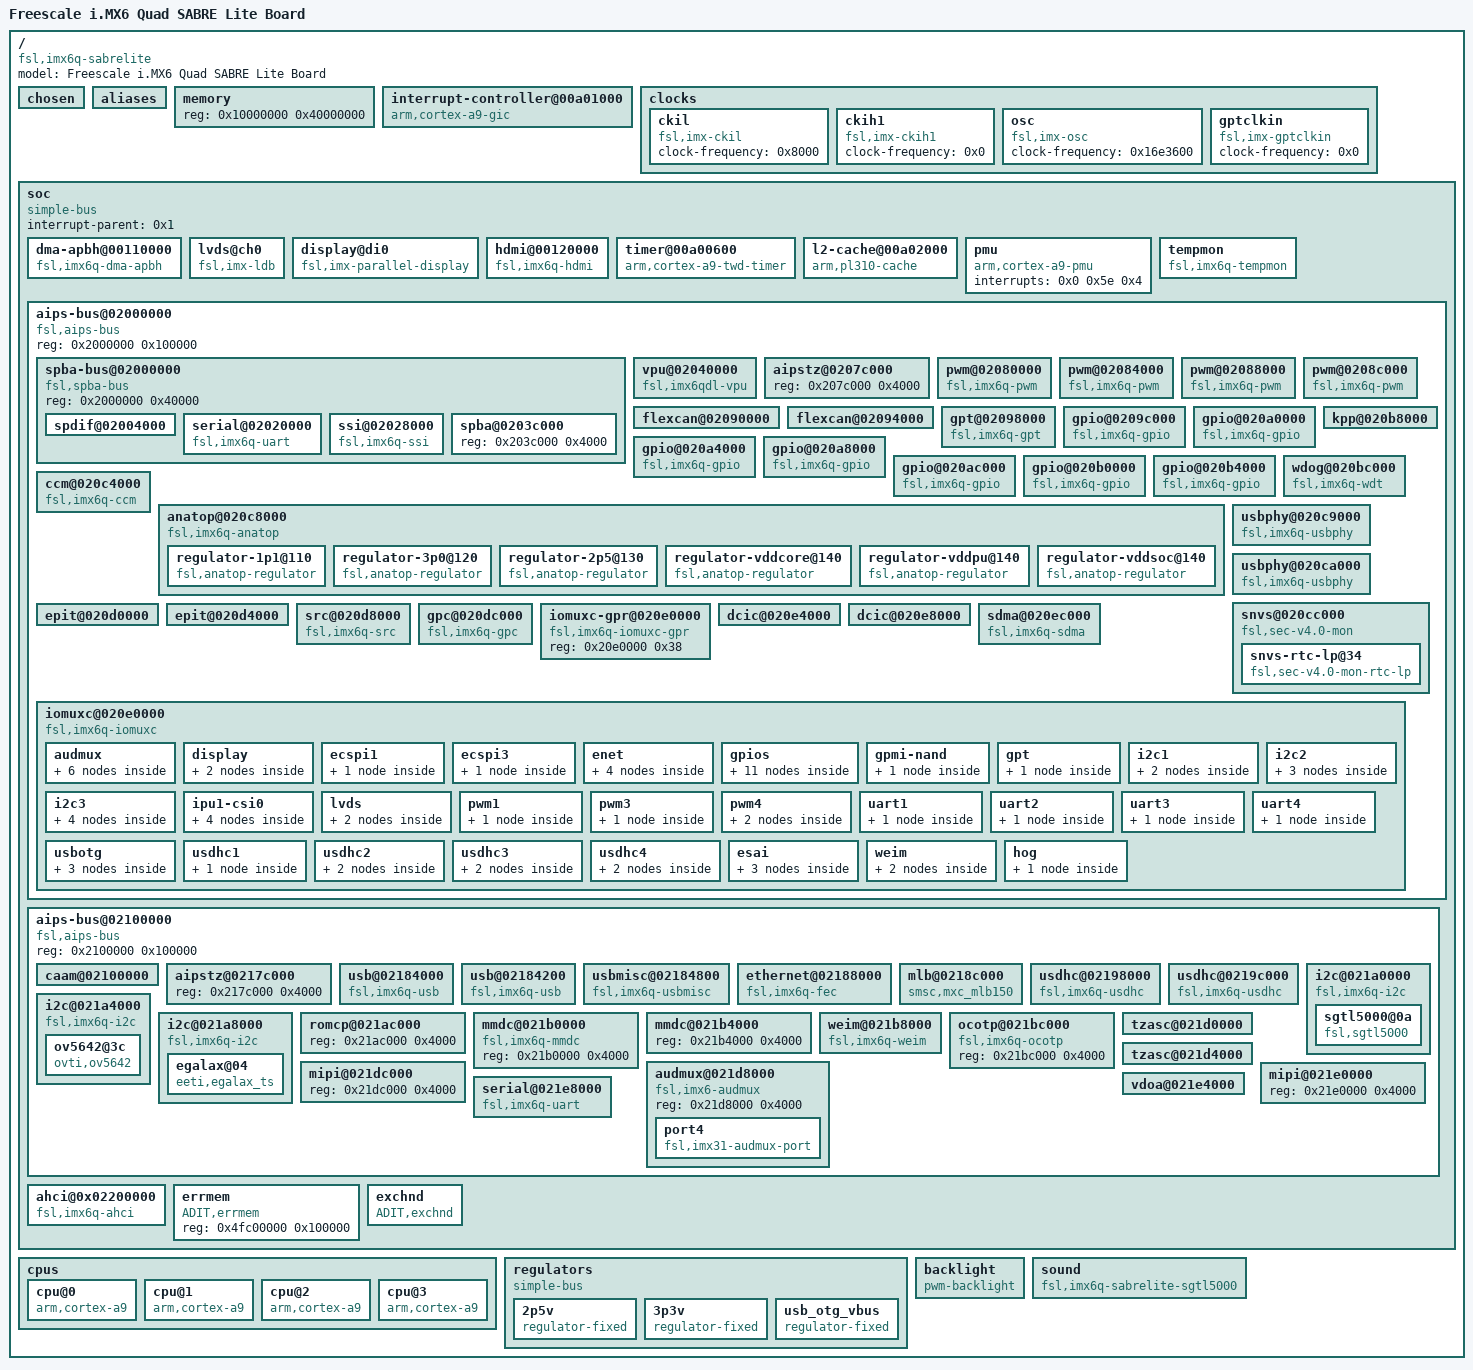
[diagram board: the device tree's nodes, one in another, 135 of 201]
/dts-v1/;

/ {
	#address-cells = <0x1>;
	#size-cells = <0x1>;
	model = "Freescale i.MX6 Quad SABRE Lite Board";
	compatible = "fsl,imx6q-sabrelite", "fsl,imx6q";

	chosen {
	   bootargs = "console=ttymxc1 root=/dev/mmcblk0p1 rw rootwait earlyprintk init_debug=1 video=mxcfb0 vmalloc=400M mem=862M fbmem=10M no_console_suspend";
//	   bootargs = "console=ttymxc1,115200 root=/dev/mmcblk0 rw rootwait earlyprintk init_debug mem=862M no_console_suspend";
	};

	aliases {
		serial0 = "/soc/aips-bus@02000000/spba-bus@02000000/serial@02020000";
		serial1 = "/soc/aips-bus@02100000/serial@021e8000";
		serial2 = "/soc/aips-bus@02100000/serial@021ec000";
		serial3 = "/soc/aips-bus@02100000/serial@021f0000";
		serial4 = "/soc/aips-bus@02100000/serial@021f4000";
		gpio0 = "/soc/aips-bus@02000000/gpio@0209c000";
		gpio1 = "/soc/aips-bus@02000000/gpio@020a0000";
		gpio2 = "/soc/aips-bus@02000000/gpio@020a4000";
		gpio3 = "/soc/aips-bus@02000000/gpio@020a8000";
		gpio4 = "/soc/aips-bus@02000000/gpio@020ac000";
		gpio5 = "/soc/aips-bus@02000000/gpio@020b0000";
		gpio6 = "/soc/aips-bus@02000000/gpio@020b4000";
	};

	memory {
		device_type = "memory";
		reg = <0x10000000 0x40000000>;
	};

	interrupt-controller@00a01000 {
		compatible = "arm,cortex-a9-gic";
		#interrupt-cells = <0x3>;
		#address-cells = <0x1>;
		#size-cells = <0x1>;
		interrupt-controller;
		reg = <0xa01000 0x1000 0xa00100 0x100>;
		linux,phandle = <0x1>;
		phandle = <0x1>;
	};

	clocks {
		#address-cells = <0x1>;
		#size-cells = <0x0>;

		ckil {
			compatible = "fsl,imx-ckil", "fixed-clock";
			clock-frequency = <0x8000>;
		};

		ckih1 {
			compatible = "fsl,imx-ckih1", "fixed-clock";
			clock-frequency = <0x0>;
		};

		osc {
			compatible = "fsl,imx-osc", "fixed-clock";
			clock-frequency = <0x16e3600>;
		};

		gptclkin {
			compatible = "fsl,imx-gptclkin", "fixed-clock";
			clock-frequency = <0x0>;
		};
	};

	soc {
		#address-cells = <0x1>;
		#size-cells = <0x1>;
		compatible = "simple-bus";
		interrupt-parent = <0x1>;
		ranges;

		dma-apbh@00110000 {
			compatible = "fsl,imx6q-dma-apbh", "fsl,imx28-dma-apbh";
			reg = <0x110000 0x2000>;
			clocks = <0x2 0x6a>;
		};

		lvds@ch0 {
			compatible = "fsl,imx-ldb";
			clocks = <0x2 0x87 0x2 0x88 0x2 0x21 0x2 0x22 0x2 0x27 0x2 0x28 0x2 0x29 0x2 0x2a>;
			clock-names = "ldb_di0", "ldb_di1", "ldb_di0_sel", "ldb_di1_sel", "ipu1_di0_sel", "ipu1_di1_sel", "ipu2_di0_sel", "ipu2_di1_sel";
			fsl,ldb-channel = <0x0>;
			status = "okay";
			crtcs = <0x3 0x4>;
			pinctrl-names = "default";
			pinctrl-0 = <0x5>;
			bgref-rmode = "internal";
		};

		display@di0 {
			compatible = "fsl,imx-parallel-display";
			status = "okay";
			xres = <0x320>;
			yres = <0x1e0>;
			clock = <0x1c9c380>;
			left_margin = <0x28>;
			right_margin = <0x28>;
			upper_margin = <0x1d>;
			lower_margin = <0xd>;
			hsync_len = <0x30>;
			vsync_len = <0x3>;
			crtcs = <0x3>;
			pinctrl-names = "default";
			pinctrl-0 = <0x8>;
			interface_pix_fmt = "rgb18";
		};

		hdmi@00120000 {
			compatible = "fsl,imx6q-hdmi", "fsl,hdmi";
			reg = <0x120000 0x9000>;
			interrupts = <0x0 0x73 0x4>;
			clocks = <0x2 0x7c 0x2 0x7b 0x2 0x4f 0x2 0x50 0x2 0x51 0x2 0x52 0x2 0x27 0x2 0x28 0x2 0x29 0x2 0x2a>;
			clock-names = "isfr", "iahb", "ipu1_di0_pre", "ipu1_di1_pre", "ipu2_di0_pre", "ipu2_di1_pre", "ipu1_di0_sel", "ipu1_di1_sel", "ipu2_di0_sel", "ipu2_di1_sel";
			status = "okay";
			crtcs = <0x3 0x6 0x4 0x7>;
			ddc = <0x9>;
		};

		timer@00a00600 {
			compatible = "arm,cortex-a9-twd-timer";
			reg = <0xa00600 0x20>;
			interrupts = <0x1 0xd 0xf01>;
		};

		l2-cache@00a02000 {
			compatible = "arm,pl310-cache";
			reg = <0xa02000 0x1000>;
			interrupts = <0x0 0x5c 0x4>;
			cache-unified;
			cache-level = <0x2>;
			arm,tag-latency = <0x4 0x2 0x3>;
			arm,data-latency = <0x4 0x2 0x3>;
			linux,phandle = <0x28>;
			phandle = <0x28>;
		};

		pmu {
			compatible = "arm,cortex-a9-pmu";
			interrupts = <0x0 0x5e 0x4>;
		};

		tempmon {
			compatible = "fsl,imx6q-tempmon";
			fsl,tempmon = <0xa>;
			fsl,tempmon-data = <0xb>;
		};

		aips-bus@02000000 {
			compatible = "fsl,aips-bus", "simple-bus";
			#address-cells = <0x1>;
			#size-cells = <0x1>;
			reg = <0x2000000 0x100000>;
			ranges;

			spba-bus@02000000 {
				compatible = "fsl,spba-bus", "simple-bus";
				#address-cells = <0x1>;
				#size-cells = <0x1>;
				reg = <0x2000000 0x40000>;
				ranges;

				spdif@02004000 {
					reg = <0x2004000 0x4000>;
					interrupts = <0x0 0x34 0x4>;
				};
/*
				ecspi@02008000 {
					#address-cells = <0x1>;
					#size-cells = <0x0>;
					compatible = "fsl,imx6q-ecspi", "fsl,imx51-ecspi";
					reg = <0x2008000 0x4000>;
					interrupts = <0x0 0x1f 0x4>;
					clocks = <0x2 0x70 0x2 0x70>;
					clock-names = "ipg", "per";
					status = "okay";
					fsl,spi-num-chipselects = <0x1>;
					cs-gpios = <0xc 0x13 0x0>;
					pinctrl-names = "default";
					pinctrl-0 = <0xd>;
					fsl,spi-dma-enable = <0x1>;
					fsl,spi-dma-events = <0x3 0x4>;
					fsl,spi-automode = <0x1>;
					fsl,spi-max-pio-trans = <0x400>;

					m25p80@0 {
						#address-cells = <0x1>;
						#size-cells = <0x1>;
						compatible = "sst,sst25vf016b";
						spi-max-frequency = <0x1312d00>;
						reg = <0x0>;
					};
				};
*/
				serial@02020000 {
					compatible = "fsl,imx6q-uart", "fsl,imx21-uart";
					reg = <0x2020000 0x4000>;
					interrupts = <0x0 0x1a 0x4>;
					clocks = <0x2 0xa0 0x2 0xa1>;
					clock-names = "ipg", "per";
					status = "okay";
				};

				ssi@02028000 {
					compatible = "fsl,imx6q-ssi", "fsl,imx21-ssi";
					reg = <0x2028000 0x4000>;
					interrupts = <0x0 0x2e 0x4>;
					clocks = <0x2 0x55 0x2 0xb2>;
					clock-names = "mclk", "ipg";
					fsl,fifo-depth = <0xf>;
					fsl,ssi-dma-events = <0x26 0x25>;
					status = "okay";
					fsl,mode = "i2s-slave";
					linux,phandle = <0x20>;
					phandle = <0x20>;
				};

				spba@0203c000 {
					reg = <0x203c000 0x4000>;
				};
			};

			vpu@02040000 {
				compatible = "fsl,imx6qdl-vpu";
				reg = <0x2040000 0x3c000>;
				interrupts = <0x0 0xc 0x4 0x0 0x3 0x4>;
			};

			aipstz@0207c000 {
				reg = <0x207c000 0x4000>;
			};

			pwm@02080000 {
				#pwm-cells = <0x3>;
				compatible = "fsl,imx6q-pwm", "fsl,imx27-pwm";
				reg = <0x2080000 0x4000>;
				interrupts = <0x0 0x53 0x4>;
				clocks = <0x2 0x3e 0x2 0x91>;
				clock-names = "ipg", "per";
			};

			pwm@02084000 {
				#pwm-cells = <0x3>;
				compatible = "fsl,imx6q-pwm", "fsl,imx27-pwm";
				reg = <0x2084000 0x4000>;
				interrupts = <0x0 0x54 0x4>;
				clocks = <0x2 0x3e 0x2 0x92>;
				clock-names = "ipg", "per";
			};

			pwm@02088000 {
				#pwm-cells = <0x3>;
				compatible = "fsl,imx6q-pwm", "fsl,imx27-pwm";
				reg = <0x2088000 0x4000>;
				interrupts = <0x0 0x55 0x4>;
				clocks = <0x2 0x3e 0x2 0x93>;
				clock-names = "ipg", "per";
			};

			pwm@0208c000 {
				#pwm-cells = <0x3>;
				compatible = "fsl,imx6q-pwm", "fsl,imx27-pwm";
				reg = <0x208c000 0x4000>;
				interrupts = <0x0 0x56 0x4>;
				clocks = <0x2 0x3e 0x2 0x94>;
				clock-names = "ipg", "per";
				pinctrl-names = "default";
				pinctrl-0 = <0xe>;
				status = "okay";
				linux,phandle = <0x2c>;
				phandle = <0x2c>;
			};

			flexcan@02090000 {
				reg = <0x2090000 0x4000>;
				interrupts = <0x0 0x6e 0x4>;
			};

			flexcan@02094000 {
				reg = <0x2094000 0x4000>;
				interrupts = <0x0 0x6f 0x4>;
			};

			gpt@02098000 {
				compatible = "fsl,imx6q-gpt";
				reg = <0x2098000 0x4000>;
				interrupts = <0x0 0x37 0x4>;
				clocks = <0x2 0x78>;
				clock-names = "ckih";
			};

			gpio@0209c000 {
				compatible = "fsl,imx6q-gpio", "fsl,imx35-gpio";
				reg = <0x209c000 0x4000>;
				interrupts = <0x0 0x42 0x4 0x0 0x43 0x4>;
				gpio-controller;
				#gpio-cells = <0x2>;
				interrupt-controller;
				#interrupt-cells = <0x2>;
				linux,phandle = <0x1e>;
				phandle = <0x1e>;
			};

			gpio@020a0000 {
				compatible = "fsl,imx6q-gpio", "fsl,imx35-gpio";
				reg = <0x20a0000 0x4000>;
				interrupts = <0x0 0x44 0x4 0x0 0x45 0x4>;
				gpio-controller;
				#gpio-cells = <0x2>;
				interrupt-controller;
				#interrupt-cells = <0x2>;
				linux,phandle = <0x1a>;
				phandle = <0x1a>;
			};

			gpio@020a4000 {
				compatible = "fsl,imx6q-gpio", "fsl,imx35-gpio";
				reg = <0x20a4000 0x4000>;
				interrupts = <0x0 0x46 0x4 0x0 0x47 0x4>;
				gpio-controller;
				#gpio-cells = <0x2>;
				interrupt-controller;
				#interrupt-cells = <0x2>;
				linux,phandle = <0xc>;
				phandle = <0xc>;
			};

			gpio@020a8000 {
				compatible = "fsl,imx6q-gpio", "fsl,imx35-gpio";
				reg = <0x20a8000 0x4000>;
				interrupts = <0x0 0x48 0x4 0x0 0x49 0x4>;
				gpio-controller;
				#gpio-cells = <0x2>;
				interrupt-controller;
				#interrupt-cells = <0x2>;
			};

			gpio@020ac000 {
				compatible = "fsl,imx6q-gpio", "fsl,imx35-gpio";
				reg = <0x20ac000 0x4000>;
				interrupts = <0x0 0x4a 0x4 0x0 0x4b 0x4>;
				gpio-controller;
				#gpio-cells = <0x2>;
				interrupt-controller;
				#interrupt-cells = <0x2>;
			};

			gpio@020b0000 {
				compatible = "fsl,imx6q-gpio", "fsl,imx35-gpio";
				reg = <0x20b0000 0x4000>;
				interrupts = <0x0 0x4c 0x4 0x0 0x4d 0x4>;
				gpio-controller;
				#gpio-cells = <0x2>;
				interrupt-controller;
				#interrupt-cells = <0x2>;
			};

			gpio@020b4000 {
				compatible = "fsl,imx6q-gpio", "fsl,imx35-gpio";
				reg = <0x20b4000 0x4000>;
				interrupts = <0x0 0x4e 0x4 0x0 0x4f 0x4>;
				gpio-controller;
				#gpio-cells = <0x2>;
				interrupt-controller;
				#interrupt-cells = <0x2>;
				linux,phandle = <0x17>;
				phandle = <0x17>;
			};

			kpp@020b8000 {
				reg = <0x20b8000 0x4000>;
				interrupts = <0x0 0x52 0x4>;
			};

			wdog@020bc000 {
				compatible = "fsl,imx6q-wdt", "fsl,imx21-wdt";
				reg = <0x20bc000 0x4000>;
				interrupts = <0x0 0x50 0x4>;
				clocks = <0x2 0x0>;
			};

			ccm@020c4000 {
				compatible = "fsl,imx6q-ccm";
				reg = <0x20c4000 0x4000>;
				interrupts = <0x0 0x57 0x4 0x0 0x58 0x4>;
				#clock-cells = <0x1>;
				linux,phandle = <0x2>;
				phandle = <0x2>;
			};

			anatop@020c8000 {
				compatible = "fsl,imx6q-anatop", "syscon", "simple-bus";
				reg = <0x20c8000 0x1000>;
				interrupts = <0x0 0x31 0x4 0x0 0x36 0x4 0x0 0x7f 0x4>;
				linux,phandle = <0xa>;
				phandle = <0xa>;

				regulator-1p1@110 {
					compatible = "fsl,anatop-regulator";
					regulator-name = "vdd1p1";
					regulator-min-microvolt = <0xc3500>;
					regulator-max-microvolt = <0x14fb18>;
					regulator-always-on;
					anatop-reg-offset = <0x110>;
					anatop-vol-bit-shift = <0x8>;
					anatop-vol-bit-width = <0x5>;
					anatop-min-bit-val = <0x4>;
					anatop-min-voltage = <0xc3500>;
					anatop-max-voltage = <0x14fb18>;
				};

				regulator-3p0@120 {
					compatible = "fsl,anatop-regulator";
					regulator-name = "vdd3p0";
					regulator-min-microvolt = <0x2ab980>;
					regulator-max-microvolt = <0x3010b0>;
					regulator-always-on;
					anatop-reg-offset = <0x120>;
					anatop-vol-bit-shift = <0x8>;
					anatop-vol-bit-width = <0x5>;
					anatop-min-bit-val = <0x0>;
					anatop-min-voltage = <0x280de8>;
					anatop-max-voltage = <0x33e140>;
				};

				regulator-2p5@130 {
					compatible = "fsl,anatop-regulator";
					regulator-name = "vdd2p5";
					regulator-min-microvolt = <0x1e8480>;
					regulator-max-microvolt = <0x29f630>;
					regulator-always-on;
					anatop-reg-offset = <0x130>;
					anatop-vol-bit-shift = <0x8>;
					anatop-vol-bit-width = <0x5>;
					anatop-min-bit-val = <0x0>;
					anatop-min-voltage = <0x1e8480>;
					anatop-max-voltage = <0x29f630>;
				};

				regulator-vddcore@140 {
					compatible = "fsl,anatop-regulator";
					regulator-name = "cpu";
					regulator-min-microvolt = <0xb1008>;
					regulator-max-microvolt = <0x162010>;
					regulator-always-on;
					anatop-reg-offset = <0x140>;
					anatop-vol-bit-shift = <0x0>;
					anatop-vol-bit-width = <0x5>;
					anatop-delay-reg-offset = <0x170>;
					anatop-delay-bit-shift = <0x18>;
					anatop-delay-bit-width = <0x2>;
					anatop-min-bit-val = <0x1>;
					anatop-min-voltage = <0xb1008>;
					anatop-max-voltage = <0x162010>;
					linux,phandle = <0x29>;
					phandle = <0x29>;
				};

				regulator-vddpu@140 {
					compatible = "fsl,anatop-regulator";
					regulator-name = "vddpu";
					regulator-min-microvolt = <0xb1008>;
					regulator-max-microvolt = <0x162010>;
					regulator-always-on;
					anatop-reg-offset = <0x140>;
					anatop-vol-bit-shift = <0x9>;
					anatop-vol-bit-width = <0x5>;
					anatop-delay-reg-offset = <0x170>;
					anatop-delay-bit-shift = <0x1a>;
					anatop-delay-bit-width = <0x2>;
					anatop-min-bit-val = <0x1>;
					anatop-min-voltage = <0xb1008>;
					anatop-max-voltage = <0x162010>;
					linux,phandle = <0x2a>;
					phandle = <0x2a>;
				};

				regulator-vddsoc@140 {
					compatible = "fsl,anatop-regulator";
					regulator-name = "vddsoc";
					regulator-min-microvolt = <0xb1008>;
					regulator-max-microvolt = <0x162010>;
					regulator-always-on;
					anatop-reg-offset = <0x140>;
					anatop-vol-bit-shift = <0x12>;
					anatop-vol-bit-width = <0x5>;
					anatop-delay-reg-offset = <0x170>;
					anatop-delay-bit-shift = <0x1c>;
					anatop-delay-bit-width = <0x2>;
					anatop-min-bit-val = <0x1>;
					anatop-min-voltage = <0xb1008>;
					anatop-max-voltage = <0x162010>;
					linux,phandle = <0x2b>;
					phandle = <0x2b>;
				};
			};

			usbphy@020c9000 {
				compatible = "fsl,imx6q-usbphy", "fsl,imx23-usbphy";
				reg = <0x20c9000 0x1000 0x20c8000 0x200>;
				interrupts = <0x0 0x2c 0x4>;
				clocks = <0x2 0xb6>;
				usbphy_reg_at_anatop;
				usbphy_need_disconnect_line_feature;
				usbphy_need_open_regulator_at_lpm;
				linux,phandle = <0x10>;
				phandle = <0x10>;
			};

			usbphy@020ca000 {
				compatible = "fsl,imx6q-usbphy", "fsl,imx23-usbphy";
				reg = <0x20ca000 0x1000 0x20c8000 0x200>;
				interrupts = <0x0 0x2d 0x4>;
				clocks = <0x2 0xb7>;
				usbphy_reg_at_anatop;
				usbphy_need_open_regulator_at_lpm;
				linux,phandle = <0x14>;
				phandle = <0x14>;
			};

			snvs@020cc000 {
				compatible = "fsl,sec-v4.0-mon", "simple-bus";
				#address-cells = <0x1>;
				#size-cells = <0x1>;
				ranges = <0x0 0x20cc000 0x4000>;

				snvs-rtc-lp@34 {
					compatible = "fsl,sec-v4.0-mon-rtc-lp";
					reg = <0x34 0x58>;
					interrupts = <0x0 0x13 0x4 0x0 0x14 0x4>;
				};
			};

			epit@020d0000 {
				reg = <0x20d0000 0x4000>;
				interrupts = <0x0 0x38 0x4>;
			};

			epit@020d4000 {
				reg = <0x20d4000 0x4000>;
				interrupts = <0x0 0x39 0x4>;
			};

			src@020d8000 {
				compatible = "fsl,imx6q-src";
				reg = <0x20d8000 0x4000>;
				interrupts = <0x0 0x5b 0x4 0x0 0x60 0x4>;
			};

			gpc@020dc000 {
				compatible = "fsl,imx6q-gpc";
				reg = <0x20dc000 0x4000>;
				interrupts = <0x0 0x59 0x4 0x0 0x5a 0x4>;
			};

			iomuxc-gpr@020e0000 {
				compatible = "fsl,imx6q-iomuxc-gpr", "syscon";
				reg = <0x20e0000 0x38>;
			};

			dcic@020e4000 {
				reg = <0x20e4000 0x4000>;
				interrupts = <0x0 0x7c 0x4>;
			};

			dcic@020e8000 {
				reg = <0x20e8000 0x4000>;
				interrupts = <0x0 0x7d 0x4>;
			};


			sdma@020ec000 {
				compatible = "fsl,imx6q-sdma", "fsl,imx35-sdma";
				reg = <0x20ec000 0x4000>;
				interrupts = <0x0 0x2 0x4>;
				clocks = <0x2 0x9b 0x2 0x9b>;
				clock-names = "ipg", "ahb";
				fsl,sdma-ram-script-name = "imx/sdma/sdma-imx6q-to1.bin";
			};


			iomuxc@020e0000 {
				compatible = "fsl,imx6q-iomuxc";
				reg = <0x20e0000 0x4000>;
				pinctrl-names = "default";
				pinctrl-0 = <0xf>;

				audmux {

					audmux-1 {
						fsl,pins = <0x54 0x368 0x7b4 0x3 0x0 0x80000000 0x35c 0x744 0x7c4 0x3 0x1 0x80000000 0x50 0x364 0x7b8 0x3 0x0 0x80000000 0x4c 0x360 0x7c8 0x3 0x0 0x80000000>;
					};

					audmux-2 {
						fsl,pins = <0x274 0x644 0x0 0x4 0x0 0x80000000 0x268 0x638 0x0 0x4 0x0 0x80000000 0x26c 0x63c 0x0 0x4 0x0 0x80000000 0x270 0x640 0x0 0x4 0x0 0x80000000>;
					};

					audmux-port-3 {
						fsl,pins = <0x268 0x638 0x0 0x4 0x0 0x80000000 0x26c 0x63c 0x0 0x4 0x0 0x80000000 0x270 0x640 0x0 0x4 0x0 0x80000000 0x274 0x644 0x0 0x4 0x0 0x80000000 0x280 0x650 0x0 0x1 0x0 0x80000000 0x284 0x654 0x0 0x1 0x0 0x80000000>;
					};

					audmux-port-4 {
						fsl,pins = <0x54 0x368 0x7b4 0x3 0x0 0x80000000 0x358 0x740 0x7bc 0x3 0x1 0x80000000 0x354 0x73c 0x7c0 0x3 0x1 0x80000000 0x35c 0x744 0x7c4 0x3 0x1 0x80000000 0x50 0x364 0x7b8 0x3 0x0 0x80000000 0x1c4 0x4d8 0x7b8 0x3 0x1 0x80000000 0x4c 0x360 0x7c8 0x3 0x0 0x80000000>;
						linux,phandle = <0x22>;
						phandle = <0x22>;
					};

					audmux-port-5 {
						fsl,pins = <0x1b0 0x4c4 0x7dc 0x3 0x0 0x80000000 0x1b4 0x4c8 0x7d0 0x3 0x0 0x80000000 0x1b8 0x4cc 0x7e0 0x3 0x0 0x80000000 0x204 0x5d4 0x7cc 0x2 0x1 0x80000000 0x1a8 0x4bc 0x7d4 0x3 0x1 0x80000000 0xb4 0x3c8 0x7d8 0x6 0x0 0x80000000>;
					};

					audmux-port-6 {
						fsl,pins = <0x160 0x474 0x0 0x2 0x0 0x80000000 0x164 0x478 0x0 0x2 0x0 0x80000000 0x168 0x47c 0x0 0x2 0x0 0x80000000 0x16c 0x480 0x0 0x2 0x0 0x80000000 0x184 0x498 0x0 0x3 0x0 0x80000000 0x188 0x49c 0x0 0x3 0x0 0x80000000>;
					};
				};

				display {

					display_1 {
						fsl,pins = <0x15c 0x470 0x0 0x0 0x0 0x80000000 0x160 0x474 0x0 0x0 0x0 0x80000000 0x164 0x478 0x0 0x0 0x0 0x80000000 0x168 0x47c 0x0 0x0 0x0 0x80000000 0x16c 0x480 0x0 0x0 0x0 0x80000000 0x170 0x484 0x0 0x0 0x0 0x80000000 0x174 0x488 0x0 0x0 0x0 0x80000000 0x178 0x48c 0x0 0x0 0x0 0x80000000 0x17c 0x490 0x0 0x0 0x0 0x80000000 0x180 0x494 0x0 0x0 0x0 0x80000000 0x184 0x498 0x0 0x0 0x0 0x80000000 0x188 0x49c 0x0 0x0 0x0 0x80000000 0x18c 0x4a0 0x0 0x0 0x0 0x80000000 0x190 0x4a4 0x0 0x0 0x0 0x80000000 0x194 0x4a8 0x0 0x0 0x0 0x80000000 0x198 0x4ac 0x0 0x0 0x0 0x80000000 0x19c 0x4b0 0x0 0x0 0x0 0x80000000 0x1a0 0x4b4 0x0 0x0 0x0 0x80000000 0x1a4 0x4b8 0x0 0x0 0x0 0x80000000 0x1a8 0x4bc 0x0 0x0 0x0 0x80000000 0x1ac 0x4c0 0x0 0x0 0x0 0x80000000 0x1b0 0x4c4 0x0 0x0 0x0 0x80000000 0x1b4 0x4c8 0x0 0x0 0x0 0x80000000>;
						linux,phandle = <0x8>;
						phandle = <0x8>;
					};

					display_2 {
						fsl,pins = <0x15c 0x470 0x0 0x1 0x0 0x80000000 0x160 0x474 0x0 0x1 0x0 0x80000000 0x164 0x478 0x0 0x1 0x0 0x80000000 0x168 0x47c 0x0 0x1 0x0 0x80000000 0x16c 0x480 0x0 0x1 0x0 0x80000000 0x170 0x484 0x0 0x1 0x0 0x80000000 0x174 0x488 0x0 0x1 0x0 0x80000000 0x178 0x48c 0x0 0x1 0x0 0x80000000 0x17c 0x490 0x0 0x1 0x0 0x80000000 0x180 0x494 0x0 0x1 0x0 0x80000000 0x184 0x498 0x0 0x1 0x0 0x80000000 0x188 0x49c 0x0 0x1 0x0 0x80000000 0x18c 0x4a0 0x0 0x1 0x0 0x80000000 0x190 0x4a4 0x0 0x1 0x0 0x80000000 0x194 0x4a8 0x0 0x1 0x0 0x80000000 0x198 0x4ac 0x0 0x1 0x0 0x80000000 0x19c 0x4b0 0x0 0x1 0x0 0x80000000 0x1a0 0x4b4 0x0 0x1 0x0 0x80000000 0x1a4 0x4b8 0x0 0x1 0x0 0x80000000 0x1a8 0x4bc 0x0 0x1 0x0 0x80000000 0x1ac 0x4c0 0x0 0x1 0x0 0x80000000 0x1b0 0x4c4 0x0 0x1 0x0 0x80000000 0x1b4 0x4c8 0x0 0x1 0x0 0x80000000>;
					};
				};

				ecspi1 {

					ecspi1grp-1 {
						fsl,pins = <0x94 0x3a8 0x7f8 0x1 0x0 0x1b0b0 0x98 0x3ac 0x7fc 0x1 0x0 0x1b0b0 0x90 0x3a4 0x7f4 0x1 0x0 0x1b0b0>;
						linux,phandle = <0xd>;
						phandle = <0xd>;
					};
				};

				ecspi3 {

					ecspi3grp-1 {
						fsl,pins = <0x178 0x48c 0x0 0x2 0x0 0x1b0b0 0x174 0x488 0x0 0x2 0x0 0x1b0b0 0x170 0x484 0x0 0x2 0x0 0x1b0b0>;
					};
				};

				enet {

					enetgrp-1 {
						fsl,pins = <0x1d0 0x4e4 0x840 0x1 0x0 0x1b0b0 0x1f4 0x508 0x0 0x1 0x0 0x1b0b0 0x58 0x36c 0x0 0x1 0x0 0x13030 0x5c 0x370 0x0 0x1 0x0 0x1b030 0x60 0x374 0x0 0x1 0x0 0x1b030 0x64 0x378 0x0 0x1 0x0 0x1b030 0x68 0x37c 0x0 0x1 0x0 0x1b030 0x74 0x388 0x0 0x1 0x0 0x13030 0x1d4 0x4e8 0x0 0x1 0x0 0x1b0b0 0x84 0x398 0x844 0x1 0x0 0x13030 0x70 0x384 0x848 0x1 0x0 0x1b030 0x78 0x38c 0x84c 0x1 0x0 0x1b030 0x7c 0x390 0x850 0x1 0x0 0x1b030 0x80 0x394 0x854 0x1 0x0 0x1b030 0x6c 0x380 0x858 0x1 0x0 0x13030 0x248 0x618 0x83c 0x2 0x1 0x4001b0a8>;
					};

					enetgrp-2 {
						fsl,pins = <0x200 0x5d0 0x840 0x1 0x1 0x1b0b0 0x208 0x5d8 0x0 0x4 0x0 0x1b0b0 0x58 0x36c 0x0 0x1 0x0 0x13030 0x5c 0x370 0x0 0x1 0x0 0x1b030 0x60 0x374 0x0 0x1 0x0 0x1b030 0x64 0x378 0x0 0x1 0x0 0x1b030 0x68 0x37c 0x0 0x1 0x0 0x1b030 0x74 0x388 0x0 0x1 0x0 0x13030 0x1d4 0x4e8 0x0 0x1 0x0 0x1b0b0 0x84 0x398 0x844 0x1 0x0 0x13030 0x70 0x384 0x848 0x1 0x0 0x1b030 0x78 0x38c 0x84c 0x1 0x0 0x1b030 0x7c 0x390 0x850 0x1 0x0 0x1b030 0x80 0x394 0x854 0x1 0x0 0x1b030 0x6c 0x380 0x858 0x1 0x0 0x13030>;
					};

					enetgrp-3 {
						fsl,pins = <0x1d0 0x4e4 0x840 0x1 0x0 0x1b0b0 0x1f4 0x508 0x0 0x1 0x0 0x1b0b0 0x58 0x36c 0x0 0x1 0x0 0x13030 0x5c 0x370 0x0 0x1 0x0 0x1b030 0x60 0x374 0x0 0x1 0x0 0x1b030 0x64 0x378 0x0 0x1 0x0 0x1b030 0x68 0x37c 0x0 0x1 0x0 0x1b030 0x74 0x388 0x0 0x1 0x0 0x13030 0x1d4 0x4e8 0x0 0x1 0x0 0x1b0b0 0x84 0x398 0x844 0x1 0x0 0x13030 0x70 0x384 0x848 0x1 0x0 0x1b030 0x78 0x38c 0x84c 0x1 0x0 0x1b030 0x7c 0x390 0x850 0x1 0x0 0x1b030 0x80 0x394 0x854 0x1 0x0 0x1b030 0x6c 0x380 0x858 0x1 0x0 0x13030 0x1e8 0x4fc 0x0 0x1 0x0 0x1b0b0>;
					};

					enetgrp-4 {
						fsl,pins = <0x1d0 0x4e4 0x840 0x1 0x0 0x1b0b0 0x1f4 0x508 0x0 0x1 0x0 0x1b0b0 0x58 0x36c 0x0 0x1 0x0 0x1b0b0 0x5c 0x370 0x0 0x1 0x0 0x1b0b0 0x60 0x374 0x0 0x1 0x0 0x1b0b0 0x64 0x378 0x0 0x1 0x0 0x1b0b0 0x68 0x37c 0x0 0x1 0x0 0x1b0b0 0x74 0x388 0x0 0x1 0x0 0x1b0b0 0x1d4 0x4e8 0x0 0x1 0x0 0x1b0b0 0x84 0x398 0x844 0x1 0x0 0x1b0b0 0x70 0x384 0x848 0x1 0x0 0x1b0b0 0x78 0x38c 0x84c 0x1 0x0 0x1b0b0 0x7c 0x390 0x850 0x1 0x0 0x1b0b0 0x80 0x394 0x854 0x1 0x0 0x1b0b0 0x6c 0x380 0x858 0x1 0x0 0x1b0b0>;
						linux,phandle = <0x15>;
						phandle = <0x15>;
					};
				};

				gpios {

					gpio_1_1 {
						fsl,pins = <0x224 0x5f4 0x0 0x5 0x0 0x80000000>;
					};

					gpio_1_13 {
						fsl,pins = <0x50 0x364 0x0 0x5 0x0 0x80000000>;
					};

					gpio_1_15 {
						fsl,pins = <0x54 0x368 0x0 0x5 0x0 0x80000000>;
					};

					gpio_2_0 {
						fsl,pins = <0x2fc 0x6e4 0x0 0x5 0x0 0x80000000>;
					};

					gpio_2_1 {
						fsl,pins = <0x300 0x6e8 0x0 0x5 0x0 0x80000000>;
					};

					gpio_2_2 {
						fsl,pins = <0x304 0x6ec 0x0 0x5 0x0 0x80000000>;
					};

					gpio_2_3 {
						fsl,pins = <0x308 0x6f0 0x0 0x5 0x0 0x80000000>;
					};

					gpio_2_28 {
						fsl,pins = <0x10c 0x420 0x0 0x5 0x0 0x80000000>;
					};

					gpio_5_4 {
						fsl,pins = <0xd4 0x3e8 0x0 0x5 0x0 0x80000000>;
					};

					gpio_5_20 {
						fsl,pins = <0x260 0x630 0x0 0x5 0x0 0x80000000>;
					};

					gpio_6_15 {
						fsl,pins = <0x2ec 0x6d4 0x0 0x5 0x0 0x80000000>;
					};
				};

				gpmi-nand {

					gpmi-nand-1 {
						fsl,pins = <0x2d4 0x6bc 0x0 0x0 0x0 0xb0b1 0x2d8 0x6c0 0x0 0x0 0x0 0xb0b1 0x2dc 0x6c4 0x0 0x0 0x0 0xb0b1 0x2e0 0x6c8 0x0 0x0 0x0 0xb000 0x2e4 0x6cc 0x0 0x0 0x0 0xb0b1 0x2e8 0x6d0 0x0 0x0 0x0 0xb0b1 0x2f4 0x6dc 0x0 0x1 0x0 0xb0b1 0x2f8 0x6e0 0x0 0x1 0x0 0xb0b1 0x2fc 0x6e4 0x0 0x0 0x0 0xb0b1 0x300 0x6e8 0x0 0x0 0x0 0xb0b1 0x304 0x6ec 0x0 0x0 0x0 0xb0b1 0x308 0x6f0 0x0 0x0 0x0 0xb0b1 0x30c 0x6f4 0x0 0x0 0x0 0xb0b1 0x310 0x6f8 0x0 0x0 0x0 0xb0b1 0x314 0x6fc 0x0 0x0 0x0 0xb0b1 0x318 0x700 0x0 0x0 0x0 0xb0b1 0x31c 0x704 0x0 0x2 0x0 0xb1>;
					};
				};

				gpt {

					gptgrp-1 {
						fsl,pins = <0x350 0x738 0x0 0x3 0x0 0x1b0b0>;
					};
				};

				i2c1 {

					i2c1grp-1 {
						fsl,pins = <0xa4 0x3b8 0x898 0x6 0x0 0x4001b0b0 0xc4 0x3d8 0x89c 0x1 0x0 0x4001b0b0>;
						linux,phandle = <0x1b>;
						phandle = <0x1b>;
					};

					i2c1grp-2 {
						fsl,pins = <0x278 0x648 0x89c 0x4 0x1 0x4001b0b0 0x27c 0x64c 0x898 0x4 0x1 0x4001b0b0>;
					};
				};

				i2c2 {

					i2c2grp-1 {
						fsl,pins = <0x8c 0x3a0 0x8a0 0x6 0x0 0x4001b0b0 0x90 0x3a4 0x8a4 0x6 0x0 0x4001b0b0>;
					};

					i2c2grp-2 {
						fsl,pins = <0x8c 0x3a0 0x8a0 0x6 0x0 0x4001b0b0 0x214 0x5e4 0x8a4 0x4 0x1 0x4001b0b0>;
					};

					i2c2grp-3 {
						fsl,pins = <0x210 0x5e0 0x8a0 0x4 0x1 0x4001b0b0 0x214 0x5e4 0x8a4 0x4 0x1 0x4001b0b0>;
						linux,phandle = <0x1d>;
						phandle = <0x1d>;
					};
				};

				i2c3 {

					i2c3grp-1 {
						fsl,pins = <0x94 0x3a8 0x8a8 0x6 0x0 0x4001b0b0 0x98 0x3ac 0x8ac 0x6 0x0 0x4001b0b0>;
					};

					i2c3grp-2 {
						fsl,pins = <0x22c 0x5fc 0x8a8 0x2 0x1 0x4001b0b0 0x230 0x600 0x8ac 0x2 0x1 0x4001b0b0>;
					};

					i2c3grp-3 {
						fsl,pins = <0x22c 0x5fc 0x8a8 0x2 0x1 0x4001b0b0 0x98 0x3ac 0x8ac 0x6 0x0 0x4001b0b0>;
					};

					i2c3grp-4 {
						fsl,pins = <0x23c 0x60c 0x8a8 0x6 0x2 0x4001b0b0 0x248 0x618 0x8ac 0x6 0x2 0x4001b0b0>;
						linux,phandle = <0x1f>;
						phandle = <0x1f>;
					};
				};

				ipu1-csi0 {

					ipu1-csi0-d4-d7 {
						fsl,pins = <0x268 0x638 0x0 0x0 0x0 0x80000000 0x26c 0x63c 0x0 0x0 0x0 0x80000000 0x270 0x640 0x0 0x0 0x0 0x80000000 0x274 0x644 0x0 0x0 0x0 0x80000000>;
					};

					ipu1-csi0-1 {
						fsl,pins = <0x278 0x648 0x0 0x0 0x0 0x80000000 0x27c 0x64c 0x0 0x0 0x0 0x80000000 0x280 0x650 0x0 0x0 0x0 0x80000000 0x284 0x654 0x0 0x0 0x0 0x80000000 0x288 0x658 0x0 0x0 0x0 0x80000000 0x28c 0x65c 0x0 0x0 0x0 0x80000000 0x290 0x660 0x0 0x0 0x0 0x80000000 0x294 0x664 0x0 0x0 0x0 0x80000000 0x298 0x668 0x0 0x0 0x0 0x80000000 0x29c 0x66c 0x0 0x0 0x0 0x80000000 0x2a0 0x670 0x0 0x0 0x0 0x80000000 0x2a4 0x674 0x0 0x0 0x0 0x80000000 0x25c 0x62c 0x0 0x0 0x0 0x80000000 0x258 0x628 0x0 0x0 0x0 0x80000000 0x264 0x634 0x0 0x0 0x0 0x80000000>;
						linux,phandle = <0x25>;
						phandle = <0x25>;
					};

					ipu1-csi0-2 {
						fsl,pins = <0x288 0x658 0x0 0x0 0x0 0x80000000 0x28c 0x65c 0x0 0x0 0x0 0x80000000 0x290 0x660 0x0 0x0 0x0 0x80000000 0x294 0x664 0x0 0x0 0x0 0x80000000 0x298 0x668 0x0 0x0 0x0 0x80000000 0x29c 0x66c 0x0 0x0 0x0 0x80000000 0x2a0 0x670 0x0 0x0 0x0 0x80000000 0x2a4 0x674 0x0 0x0 0x0 0x80000000 0x25c 0x62c 0x0 0x0 0x0 0x80000000 0x258 0x628 0x0 0x0 0x0 0x80000000 0x264 0x634 0x0 0x0 0x0 0x80000000>;
					};

					ipu1-csi0-data-en {
						fsl,pins = <0x260 0x630 0x0 0x0 0x0 0x80000000>;
						linux,phandle = <0x26>;
						phandle = <0x26>;
					};
				};

				lvds {

					lvdsgrp-0 {
						fsl,pins = <0x0 0x0 0x0 0x0 0x0 0x80000000 0x0 0x0 0x0 0x0 0x0 0x80000000 0x0 0x0 0x0 0x0 0x0 0x80000000 0x0 0x0 0x0 0x0 0x0 0x80000000 0x0 0x0 0x0 0x0 0x0 0x80000000>;
						linux,phandle = <0x5>;
						phandle = <0x5>;
					};

					lvdsgrp-1 {
						fsl,pins = <0x0 0x0 0x0 0x0 0x0 0x80000000 0x0 0x0 0x0 0x0 0x0 0x80000000 0x0 0x0 0x0 0x0 0x0 0x80000000 0x0 0x0 0x0 0x0 0x0 0x80000000 0x0 0x0 0x0 0x0 0x0 0x80000000>;
					};
				};

				pwm1 {

					pwm1grp-1 {
						fsl,pins = <0x344 0x72c 0x0 0x3 0x0 0x80000000>;
					};
				};

				pwm3 {

					pwm3grp-1 {
						fsl,pins = <0x320 0x708 0x0 0x2 0x0 0x80000000>;
					};
				};

				pwm4 {

					pwm4grp-1 {
						fsl,pins = <0x324 0x70c 0x0 0x2 0x0 0x80000000>;
					};

					pwm4grp-2 {
						fsl,pins = <0x348 0x730 0x0 0x2 0x0 0x80000000>;
						linux,phandle = <0xe>;
						phandle = <0xe>;
					};
				};

				uart1 {

					uart1grp-1 {
						fsl,pins = <0x280 0x650 0x0 0x3 0x0 0x1b0b0 0x284 0x654 0x920 0x3 0x1 0x1b0b0>;
					};
				};

				uart2 {

					uart2grp-1 {
						fsl,pins = <0xbc 0x3d0 0x0 0x4 0x0 0x1b0b0 0xc0 0x3d4 0x928 0x4 0x1 0x1b0b0>;
						linux,phandle = <0x24>;
						phandle = <0x24>;
					};
				};

				uart3 {

					uart3grp-1 {
						fsl,pins = <0x2f4 0x6dc 0x0 0x2 0x0 0x1b0b0 0x2f8 0x6e0 0x930 0x2 0x3 0x1b0b0 0xcc 0x3e0 0x0 0x4 0x0 0x1b0b0 0xb0 0x3c4 0x92c 0x2 0x1 0x1b0b0>;
					};
				};

				uart4 {

					uart4grp-1 {
						fsl,pins = <0x1f8 0x5c8 0x0 0x4 0x0 0x1b0b0 0x1fc 0x5cc 0x938 0x4 0x1 0x1b0b0>;
					};
				};

				usbotg {

					usbotggrp-1 {
						fsl,pins = <0x224 0x5f4 0x0 0x3 0x0 0x1b0b0>;
						linux,phandle = <0x13>;
						phandle = <0x13>;
					};

					usbotggrp-2 {
						fsl,pins = <0x1d8 0x4ec 0x0 0x0 0x0 0x1b0b0 0xa4 0x3b8 0x944 0x4 0x0 0x80000000 0xa8 0x3bc 0x0 0x4 0x0 0x80000000>;
					};

					usbotggrp-3 {
						fsl,pins = <0x1d8 0x4ec 0x0 0x0 0x0 0x1b0b0 0x31c 0x704 0x0 0x1 0x0 0x80000000>;
					};
				};

				usdhc1 {

					usdhc1grp-1 {
						fsl,pins = <0x348 0x730 0x0 0x0 0x0 0x17071 0x350 0x738 0x0 0x0 0x0 0x10071 0x340 0x728 0x0 0x0 0x0 0x17071 0x33c 0x724 0x0 0x0 0x0 0x17071 0x34c 0x734 0x0 0x0 0x0 0x17071 0x344 0x72c 0x0 0x0 0x0 0x17071>;
					};
				};

				usdhc2 {

					usdhc2grp-1 {
						fsl,pins = <0x358 0x740 0x0 0x0 0x0 0x1b0b0 0x354 0x73c 0x0 0x0 0x0 0x1b0b0 0x54 0x368 0x0 0x0 0x0 0x1b0b0 0x4c 0x360 0x0 0x0 0x0 0x1b0b0 0x50 0x364 0x0 0x0 0x0 0x1b0b0 0x35c 0x744 0x0 0x0 0x0 0x1b0b0 0x30c 0x6f4 0x0 0x1 0x0 0x1b0b0 0x310 0x6f8 0x0 0x1 0x0 0x1b0b0 0x314 0x6fc 0x0 0x1 0x0 0x1b0b0 0x318 0x700 0x0 0x1 0x0 0x1b0b0>;
					};

					usdhc2grp-2 {
						fsl,pins = <0x358 0x740 0x0 0x0 0x0 0x1b0b0 0x354 0x73c 0x0 0x0 0x0 0x1b0b0 0x54 0x368 0x0 0x0 0x0 0x1b0b0 0x4c 0x360 0x0 0x0 0x0 0x1b0b0 0x50 0x364 0x0 0x0 0x0 0x1b0b0 0x35c 0x744 0x0 0x0 0x0 0x1b0b0>;
					};
				};

				usdhc3 {

					usdhc3grp-1 {
						fsl,pins = <0x2b8 0x6a0 0x0 0x0 0x0 0x1b0b0 0x2bc 0x6a4 0x0 0x0 0x0 0x1b0b0 0x2c0 0x6a8 0x0 0x0 0x0 0x1b0b0 0x2c4 0x6ac 0x0 0x0 0x0 0x1b0b0 0x2c8 0x6b0 0x0 0x0 0x0 0x1b0b0 0x2cc 0x6b4 0x0 0x0 0x0 0x1b0b0 0x2b4 0x69c 0x0 0x0 0x0 0x1b0b0 0x2b0 0x698 0x0 0x0 0x0 0x1b0b0 0x2ac 0x694 0x0 0x0 0x0 0x1b0b0 0x2a8 0x690 0x0 0x0 0x0 0x1b0b0 0x250 0x620 0x0 0x2 0x0 0x1b0b0>;
					};

					usdhc3grp-2 {
						fsl,pins = <0x2b8 0x6a0 0x0 0x0 0x0 0x1b0b0 0x2bc 0x6a4 0x0 0x0 0x0 0x1b0b0 0x2c0 0x6a8 0x0 0x0 0x0 0x1b0b0 0x2c4 0x6ac 0x0 0x0 0x0 0x1b0b0 0x2c8 0x6b0 0x0 0x0 0x0 0x1b0b0 0x2cc 0x6b4 0x0 0x0 0x0 0x1b0b0>;
						linux,phandle = <0x16>;
						phandle = <0x16>;
					};
				};

				usdhc4 {

					usdhc4grp-1 {
						fsl,pins = <0x2f4 0x6dc 0x0 0x0 0x0 0x1b0b0 0x2f8 0x6e0 0x0 0x0 0x0 0x1b0b0 0x31c 0x704 0x0 0x1 0x0 0x1b0b0 0x320 0x708 0x0 0x1 0x0 0x1b0b0 0x324 0x70c 0x0 0x1 0x0 0x1b0b0 0x328 0x710 0x0 0x1 0x0 0x1b0b0 0x32c 0x714 0x0 0x1 0x0 0x1b0b0 0x330 0x718 0x0 0x1 0x0 0x1b0b0 0x334 0x71c 0x0 0x1 0x0 0x1b0b0 0x338 0x720 0x0 0x1 0x0 0x1b0b0>;
					};

					usdhc4grp-2 {
						fsl,pins = <0x2f4 0x6dc 0x0 0x0 0x0 0x1b0b0 0x2f8 0x6e0 0x0 0x0 0x0 0x1b0b0 0x31c 0x704 0x0 0x1 0x0 0x1b0b0 0x320 0x708 0x0 0x1 0x0 0x1b0b0 0x324 0x70c 0x0 0x1 0x0 0x1b0b0 0x328 0x710 0x0 0x1 0x0 0x1b0b0>;
						linux,phandle = <0x19>;
						phandle = <0x19>;
					};
				};

				esai {

					esaigrp-1 {
						fsl,pins = <0x1d0 0x4e4 0x86c 0x2 0x0 0x1b0b0 0x1d8 0x4ec 0x864 0x2 0x0 0x1b0b0 0x1dc 0x4f0 0x870 0x2 0x0 0x1b0b0 0x1e0 0x4f4 0x860 0x2 0x0 0x1b0b0 0x1e4 0x4f8 0x868 0x2 0x0 0x1b0b0 0x1ec 0x500 0x87c 0x2 0x0 0x1b0b0 0x1e8 0x4fc 0x880 0x2 0x0 0x1b0b0 0x1f0 0x504 0x884 0x2 0x0 0x1b0b0 0x1f4 0x508 0x888 0x2 0x0 0x1b0b0 0x2ec 0x6d4 0x874 0x2 0x1 0x1b0b0 0x2f0 0x6d8 0x878 0x2 0x1 0x1b0b0>;
					};

					esaigrp-2 {
						fsl,pins = <0x1dc 0x4f0 0x870 0x2 0x0 0x1b0b0 0x1e0 0x4f4 0x860 0x2 0x0 0x1b0b0 0x1d0 0x4e4 0x86c 0x2 0x0 0x1b0b0 0x228 0x5f8 0x85c 0x0 0x1 0x1b0b0 0x24c 0x61c 0x874 0x0 0x0 0x1b0b0 0x2f0 0x6d8 0x878 0x2 0x1 0x1b0b0 0x23c 0x60c 0x87c 0x0 0x1 0x1b0b0 0x1ec 0x500 0x87c 0x2 0x0 0x1b0b0 0x1f0 0x504 0x884 0x2 0x0 0x1b0b0 0x1f4 0x508 0x888 0x2 0x0 0x1b0b0>;
					};

					esaigrp-3 {
						fsl,pins = <0x1dc 0x4f0 0x870 0x2 0x0 0x1b0b0 0x1e0 0x4f4 0x860 0x2 0x0 0x1b0b0 0x1d0 0x4e4 0x86c 0x2 0x0 0x1b0b0 0x1d4 0x4e8 0x85c 0x2 0x0 0x1b0b0 0x2ec 0x6d4 0x874 0x2 0x1 0x1b0b0 0x250 0x620 0x878 0x0 0x0 0x1b0b0 0x1f0 0x504 0x884 0x2 0x0 0x1b0b0 0x1f4 0x508 0x888 0x2 0x0 0x1b0b0>;
					};
				};

				weim {

					weim_cs0grp-1 {
						fsl,pins = <0xf8 0x40c 0x0 0x0 0x0 0xb0b1>;
					};

					weimnorgrp-1 {
						fsl,pins = <0x100 0x414 0x0 0x0 0x0 0xb0b1 0x104 0x418 0x0 0x0 0x0 0xb0b1 0x154 0x468 0x0 0x0 0x0 0xb060 0x90 0x3a4 0x0 0x0 0x0 0x1b0b0 0x94 0x3a8 0x0 0x0 0x0 0x1b0b0 0x98 0x3ac 0x0 0x0 0x0 0x1b0b0 0x9c 0x3b0 0x0 0x0 0x0 0x1b0b0 0xa0 0x3b4 0x0 0x0 0x0 0x1b0b0 0xa4 0x3b8 0x0 0x0 0x0 0x1b0b0 0xa8 0x3bc 0x0 0x0 0x0 0x1b0b0 0xac 0x3c0 0x0 0x0 0x0 0x1b0b0 0xb4 0x3c8 0x0 0x0 0x0 0x1b0b0 0xb8 0x3cc 0x0 0x0 0x0 0x1b0b0 0xbc 0x3d0 0x0 0x0 0x0 0x1b0b0 0xc0 0x3d4 0x0 0x0 0x0 0x1b0b0 0xc4 0x3d8 0x0 0x0 0x0 0x1b0b0 0xc8 0x3dc 0x0 0x0 0x0 0x1b0b0 0xcc 0x3e0 0x0 0x0 0x0 0x1b0b0 0xd0 0x3e4 0x0 0x0 0x0 0x1b0b0 0xd8 0x3ec 0x0 0x0 0x0 0xb0b1 0xdc 0x3f0 0x0 0x0 0x0 0xb0b1 0xe0 0x3f4 0x0 0x0 0x0 0xb0b1 0xe4 0x3f8 0x0 0x0 0x0 0xb0b1 0xe8 0x3fc 0x0 0x0 0x0 0xb0b1 0xec 0x400 0x0 0x0 0x0 0xb0b1 0xf0 0x404 0x0 0x0 0x0 0xb0b1 0xf4 0x408 0x0 0x0 0x0 0xb0b1 0x150 0x464 0x0 0x0 0x0 0xb0b1 0x14c 0x460 0x0 0x0 0x0 0xb0b1 0x148 0x45c 0x0 0x0 0x0 0xb0b1 0x144 0x458 0x0 0x0 0x0 0xb0b1 0x140 0x454 0x0 0x0 0x0 0xb0b1 0x13c 0x450 0x0 0x0 0x0 0xb0b1 0x138 0x44c 0x0 0x0 0x0 0xb0b1 0x134 0x448 0x0 0x0 0x0 0xb0b1 0x130 0x444 0x0 0x0 0x0 0xb0b1 0x12c 0x440 0x0 0x0 0x0 0xb0b1 0x128 0x43c 0x0 0x0 0x0 0xb0b1 0x124 0x438 0x0 0x0 0x0 0xb0b1 0x120 0x434 0x0 0x0 0x0 0xb0b1 0x11c 0x430 0x0 0x0 0x0 0xb0b1 0x118 0x42c 0x0 0x0 0x0 0xb0b1 0x114 0x428 0x0 0x0 0x0 0xb0b1>;
					};
				};

				hog {

					hoggrp {
						fsl,pins = <0x314 0x6fc 0x0 0x5 0x0 0x80000000 0x318 0x700 0x0 0x5 0x0 0x80000000 0x9c 0x3b0 0x0 0x5 0x0 0x80000000 0xa8 0x3bc 0x0 0x5 0x0 0x80000000 0xac 0x3c0 0x0 0x5 0x0 0x80000000 0x2b0 0x698 0x0 0x5 0x0 0x80000000 0x2b4 0x69c 0x0 0x5 0x0 0x1f0b0 0x220 0x5f0 0x0 0x0 0x0 0x80000000 0x340 0x728 0x0 0x5 0x0 0x80000000 0x230 0x600 0x0 0x5 0x0 0x80000000 0x244 0x614 0x0 0x5 0x0 0x80000000 0x22c 0x5fc 0x0 0x4 0x0 0x80000000>;
						linux,phandle = <0xf>;
						phandle = <0xf>;
					};
				};
			};
		};

		aips-bus@02100000 {
			compatible = "fsl,aips-bus", "simple-bus";
			#address-cells = <0x1>;
			#size-cells = <0x1>;
			reg = <0x2100000 0x100000>;
			ranges;

			caam@02100000 {
				reg = <0x2100000 0x40000>;
				interrupts = <0x0 0x69 0x4 0x0 0x6a 0x4>;
			};

			aipstz@0217c000 {
				reg = <0x217c000 0x4000>;
			};

			usb@02184000 {
				compatible = "fsl,imx6q-usb", "fsl,imx27-usb";
				reg = <0x2184000 0x200>;
				interrupts = <0x0 0x2b 0x4>;
				clocks = <0x2 0xa2>;
				fsl,usbphy = <0x10>;
				fsl,usbmisc = <0x11 0x0>;
				status = "okay";
				vbus-supply = <0x12>;
				pinctrl-names = "default";
				pinctrl-0 = <0x13>;
				disable-over-current;
			};

			usb@02184200 {
				compatible = "fsl,imx6q-usb", "fsl,imx27-usb";
				reg = <0x2184200 0x200>;
				interrupts = <0x0 0x28 0x4>;
				clocks = <0x2 0xa2>;
				fsl,usbphy = <0x14>;
				fsl,usbmisc = <0x11 0x1>;
				status = "okay";
			};

			usbmisc@02184800 {
				#index-cells = <0x1>;
				compatible = "fsl,imx6q-usbmisc";
				reg = <0x2184800 0x200>;
				clocks = <0x2 0xa2>;
				status = "okay";
				linux,phandle = <0x11>;
				phandle = <0x11>;
			};


			ethernet@02188000 {
				compatible = "fsl,imx6q-fec";
				reg = <0x2188000 0x4000>;
				interrupts = <0x0 0x76 0x4 0x0 0x77 0x4>;
				clocks = <0x2 0x75 0x2 0x75 0x2 0xbe>;
				clock-names = "ipg", "ahb", "ptp";
				status = "okay";
				pinctrl-names = "default";
				pinctrl-0 = <0x15>;
				phy-mode = "mii";
				phy-reset-gpios = <0xc 0x17 0x0>;
			};


			mlb@0218c000 {
				compatible = "smsc,mxc_mlb150";
				reg = <0x218c000 0x4000>;
				interrupts = <0x0 0x35 0x4 0x0 0x75 0x4 0x0 0x7e 0x4>;
				clocks = <0x2 0x8b>;
				clock-names = "mlb";
			};

			usdhc@02198000 {
				compatible = "fsl,imx6q-usdhc";
				reg = <0x2198000 0x4000>;
				interrupts = <0x0 0x18 0x4>;
				clocks = <0x2 0xa5 0x2 0xa5 0x2 0xa5>;
				clock-names = "ipg", "ahb", "per";
				bus-width = <0x4>;
				status = "okay";
				pinctrl-names = "default";
				pinctrl-0 = <0x16>;
				cd-gpios = <0x17 0x0 0x0>;
				wp-gpios = <0x17 0x1 0x0>;
				vmmc-supply = <0x18>;
				fsl,mmcblk_devidx = <0x0>;
			};


			usdhc@0219c000 {
				compatible = "fsl,imx6q-usdhc";
				reg = <0x219c000 0x4000>;
				interrupts = <0x0 0x19 0x4>;
				clocks = <0x2 0xa6 0x2 0xa6 0x2 0xa6>;
				clock-names = "ipg", "ahb", "per";
				bus-width = <0x4>;
				status = "okay";
				pinctrl-names = "default";
				pinctrl-0 = <0x19>;
				cd-gpios = <0x1a 0x6 0x0>;
				wp-gpios = <0x1a 0x7 0x0>;
				vmmc-supply = <0x18>;
				fsl,mmcblk_devidx = <0x1>;
			};

			i2c@021a0000 {
				#address-cells = <0x1>;
				#size-cells = <0x0>;
				compatible = "fsl,imx6q-i2c", "fsl,imx21-i2c";
				reg = <0x21a0000 0x4000>;
				interrupts = <0x0 0x24 0x4>;
				clocks = <0x2 0x7d>;
				status = "okay";
				clock-frequency = <0x186a0>;
				pinctrl-names = "default";
				pinctrl-0 = <0x1b>;

				sgtl5000@0a {
					compatible = "fsl,sgtl5000";
					reg = <0xa>;
					clocks = <0x2 0xa9>;
					VDDA-supply = <0x1c>;
					VDDIO-supply = <0x18>;
					linux,phandle = <0x2d>;
					phandle = <0x2d>;
				};
			};

			i2c@021a4000 {
				#address-cells = <0x1>;
				#size-cells = <0x0>;
				compatible = "fsl,imx6q-i2c", "fsl,imx21-i2c";
				reg = <0x21a4000 0x4000>;
				interrupts = <0x0 0x25 0x4>;
				clocks = <0x2 0x7e>;
				status = "okay";
				clock-frequency = <0x186a0>;
				pinctrl-names = "default";
				pinctrl-0 = <0x1d>;
				linux,phandle = <0x9>;
				phandle = <0x9>;

				ov5642@3c {
					compatible = "ovti,ov5642";
					clocks = <0x2 0xc8>;
					clock-names = "xclk";
					reg = <0x3c>;
					xclk = <0x16e3600>;
					reset-gpios = <0x1e 0x8 0x0>;
					pwdn-gpios = <0x1e 0x6 0x0>;
					gp-gpios = <0x1e 0x10 0x0>;
				};
			};

			i2c@021a8000 {
				#address-cells = <0x1>;
				#size-cells = <0x0>;
				compatible = "fsl,imx6q-i2c", "fsl,imx21-i2c";
				reg = <0x21a8000 0x4000>;
				interrupts = <0x0 0x26 0x4>;
				clocks = <0x2 0x7f>;
				status = "okay";
				clock-frequency = <0x61a80>;
				pinctrl-names = "default";
				pinctrl-0 = <0x1f>;

				egalax@04 {
					compatible = "eeti,egalax_ts";
					reg = <0x4>;
					interrupt-parent = <0x1e>;
					interrupts = <0x9 0x8>;
					wakeup-gpios = <0x1e 0x9 0x0>;
				};
			};

			romcp@021ac000 {
				reg = <0x21ac000 0x4000>;
			};

			mmdc@021b0000 {
				compatible = "fsl,imx6q-mmdc";
				reg = <0x21b0000 0x4000>;
			};

			mmdc@021b4000 {
				reg = <0x21b4000 0x4000>;
			};

			weim@021b8000 {
				compatible = "fsl,imx6q-weim";
				reg = <0x21b8000 0x4000>;
				interrupts = <0x0 0xe 0x4>;
				clocks = <0x2 0xc4>;
			};

			ocotp@021bc000 {
				compatible = "fsl,imx6q-ocotp", "syscon";
				reg = <0x21bc000 0x4000>;
				linux,phandle = <0xb>;
				phandle = <0xb>;
			};

			tzasc@021d0000 {
				reg = <0x21d0000 0x4000>;
				interrupts = <0x0 0x6c 0x4>;
			};

			tzasc@021d4000 {
				reg = <0x21d4000 0x4000>;
				interrupts = <0x0 0x6d 0x4>;
			};

			audmux@021d8000 {
				compatible = "fsl,imx6-audmux", "simple-bus";
				reg = <0x21d8000 0x4000>;
				status = "okay";

				port4 {
					compatible = "fsl,imx31-audmux-port";
					status = "okay";
					num = <0x4>;
					pinctrl-names = "default";
					pinctrl-0 = <0x22>;
				};
			};

			mipi@021dc000 {
				reg = <0x21dc000 0x4000>;
			};

			mipi@021e0000 {
				reg = <0x21e0000 0x4000>;
			};

			vdoa@021e4000 {
				reg = <0x21e4000 0x4000>;
				interrupts = <0x0 0x12 0x4>;
			};

			serial@021e8000 {
				compatible = "fsl,imx6q-uart", "fsl,imx21-uart";
				reg = <0x21e8000 0x4000>;
				interrupts = <0x0 0x1b 0x4>;
				clocks = <0x2 0xa0 0x2 0xa1>;
				clock-names = "ipg", "per";
				status = "okay";
				pinctrl-names = "default";
				pinctrl-0 = <0x24>;
			};
		};
/*
		ipu@02400000 {
			compatible = "fsl,imx6q-ipu", "simple-bus";
			reg = <0x2400000 0x400000>;
			interrupts = <0x0 0x6 0x4 0x0 0x5 0x4>;
			clocks = <0x2 0x82 0x2 0x83 0x2 0x84>;
			clock-names = "bus", "di0", "di1";
			status = "okay";

			crtc@di0 {
				compatible = "fsl,imx-ipuv3-crtc";
				di = <0x0>;
				dc = <0x5>;
				dp = <0x0>;
				idmac = <0x17>;
				linux,phandle = <0x3>;
				phandle = <0x3>;
			};

			crtc@di1 {
				compatible = "fsl,imx-ipuv3-crtc";
				di = <0x1>;
				dc = <0x1>;
				idmac = <0x1c>;
				linux,phandle = <0x6>;
				phandle = <0x6>;
			};

			plane@di0 {
				compatible = "fsl,imx-ipuv3-plane";
				crtcs = <0x3>;
				dp = <0x1>;
				idmac = <0x1b>;
			};

			v4l2-capture {
				compatible = "fsl,imx6-v4l2-capture";
				idmac = <0x0 0x14 0x2d 0x30 0x15 0x2e 0x31>;
				csi = <0x0>;
				status = "okay";
				pinctrl-names = "default";
				pinctrl-0 = <0x25 0x26>;
			};

			v4l2-mem2mem {
				compatible = "fsl,imx6-v4l2-mem2mem";
				idmac = <0xb 0x16 0x2f 0x32>;
				status = "okay";
			};

			v4l2-output {
				compatible = "fsl,imx6-v4l2-output";
				idmac = <0xb 0x16 0x2f 0x32>;
				status = "okay";
			};
		};

		ipu@02800000 {
			compatible = "fsl,imx6q-ipu", "simple-bus";
			reg = <0x2800000 0x400000>;
			interrupts = <0x0 0x8 0x4 0x0 0x7 0x4>;
			clocks = <0x2 0x85 0x2 0x86 0x2 0x89>;
			clock-names = "bus", "di0", "di1";
			status = "okay";

			crtc@di0 {
				compatible = "fsl,imx-ipuv3-crtc";
				di = <0x0>;
				dc = <0x5>;
				dp = <0x0>;
				idmac = <0x17>;
				linux,phandle = <0x4>;
				phandle = <0x4>;
			};

			crtc@di1 {
				compatible = "fsl,imx-ipuv3-crtc";
				di = <0x1>;
				dc = <0x1>;
				idmac = <0x1c>;
				linux,phandle = <0x7>;
				phandle = <0x7>;
			};

			plane@di0 {
				compatible = "fsl,imx-ipuv3-plane";
				crtcs = <0x4>;
				dp = <0x1>;
				idmac = <0x1b>;
			};

			v4l2-mem2mem {
				compatible = "fsl,imx6-v4l2-mem2mem";
				idmac = <0xb 0x16 0x2f 0x32>;
				status = "okay";
			};

			v4l2-output {
				compatible = "fsl,imx6-v4l2-output";
				idmac = <0xb 0x16 0x2f 0x32>;
				status = "okay";
			};
		};
*/
/*
		galcore@virtual {
			compatible = "viv,galcore";
			reg = <0x130000 0x4000 0x134000 0x4000 0x2204000 0x4000 0x0 0x0>;
			reg-names = "iobase_3d", "iobase_2d", "iobase_vg", "phys_baseaddr";
			interrupts = <0x0 0x9 0x4 0x0 0xa 0x4 0x0 0xb 0x4>;
			interrupt-names = "irq_3d", "irq_2d", "irq_vg";
		};
*/

		ahci@0x02200000 {
			compatible = "fsl,imx6q-ahci";
			reg = <0x2200000 0x4000>;
			interrupts = <0x0 0x27 0x4>;
			clocks = <0x2 0x9a 0x2 0xbb 0x2 0x69>;
			clock-names = "ahci", "ahci_phy", "ahci_dma";
			status = "okay";
		};

		errmem {
			compatible = "ADIT,errmem";
			reg = <0x4fc00000 0x100000>;
		};

		exchnd {
			compatible = "ADIT,exchnd";
		};
	};

	cpus {
		#address-cells = <0x1>;
		#size-cells = <0x0>;

		cpu@0 {
			compatible = "arm,cortex-a9";
			device_type = "cpu";
			reg = <0x0>;
			next-level-cache = <0x28>;
			operating-points = <0x124f80 0x137478 0xf32a0 0x1312d0 0xc15c0 0x118c30 0x60ae0 0xe7ef0>;
			clock-latency = <0xee6c>;
			clocks = <0x2 0x68 0x2 0x6 0x2 0x10 0x2 0x11 0x2 0xaa>;
			clock-names = "arm", "pll2_pfd2_396m", "step", "pll1_sw", "pll1_sys";
			arm-supply = <0x29>;
			pu-supply = <0x2a>;
			soc-supply = <0x2b>;
		};

		cpu@1 {
			compatible = "arm,cortex-a9";
			device_type = "cpu";
			reg = <0x1>;
			next-level-cache = <0x28>;
		};

		cpu@2 {
			compatible = "arm,cortex-a9";
			device_type = "cpu";
			reg = <0x2>;
			next-level-cache = <0x28>;
		};

		cpu@3 {
			compatible = "arm,cortex-a9";
			device_type = "cpu";
			reg = <0x3>;
			next-level-cache = <0x28>;
		};
	};

	regulators {
		compatible = "simple-bus";

		2p5v {
			compatible = "regulator-fixed";
			regulator-name = "2P5V";
			regulator-min-microvolt = <0x2625a0>;
			regulator-max-microvolt = <0x2625a0>;
			regulator-always-on;
			linux,phandle = <0x1c>;
			phandle = <0x1c>;
		};

		3p3v {
			compatible = "regulator-fixed";
			regulator-name = "3P3V";
			regulator-min-microvolt = <0x325aa0>;
			regulator-max-microvolt = <0x325aa0>;
			regulator-always-on;
			linux,phandle = <0x18>;
			phandle = <0x18>;
		};

		usb_otg_vbus {
			compatible = "regulator-fixed";
			regulator-name = "usb_otg_vbus";
			regulator-min-microvolt = <0x4c4b40>;
			regulator-max-microvolt = <0x4c4b40>;
			gpio = <0xc 0x16 0x0>;
			enable-active-high;
			linux,phandle = <0x12>;
			phandle = <0x12>;
		};
	};

	backlight {
		compatible = "pwm-backlight";
		pwms = <0x2c 0x0 0xc350 0x0>;
		brightness-levels = <0x0 0x4 0x8 0x10 0x20 0x40 0x80 0xff>;
		default-brightness-level = <0x7>;
	};

	sound {
		compatible = "fsl,imx6q-sabrelite-sgtl5000", "fsl,imx-audio-sgtl5000";
		model = "imx6q-sabrelite-sgtl5000";
		ssi-controller = <0x20>;
		audio-codec = <0x2d>;
		audio-routing = "MIC_IN", "Mic Jack", "Mic Jack", "Mic Bias", "Headphone Jack", "HP_OUT";
		mux-int-port = <0x1>;
		mux-ext-port = <0x4>;
	};
};
